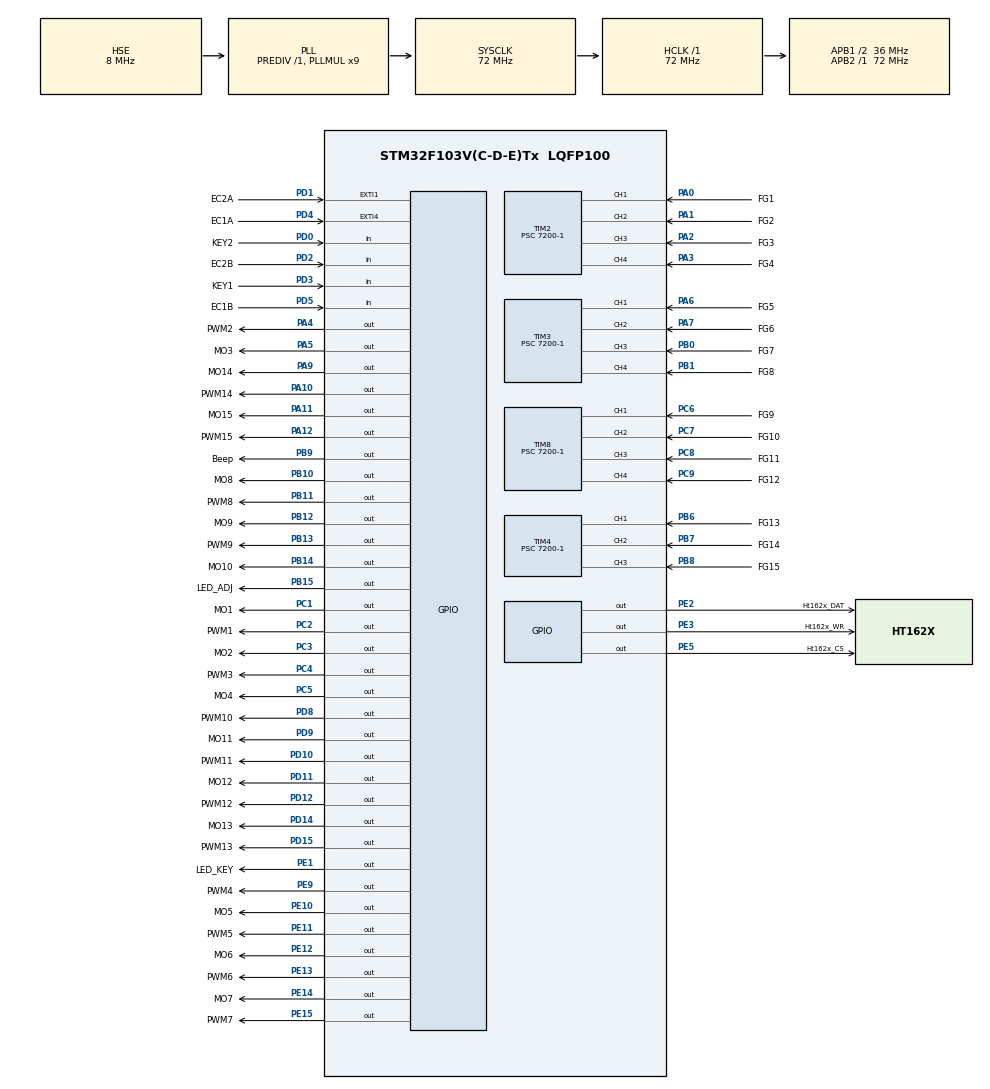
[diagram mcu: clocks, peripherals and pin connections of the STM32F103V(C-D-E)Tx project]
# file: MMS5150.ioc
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Mcu.Family=STM32F1
Mcu.Name=STM32F103V(C-D-E)Tx
Mcu.Package=LQFP100
NVIC.EXTI1_IRQn=true\:0\:0\:false\:false\:true\:true\:true\:true
NVIC.EXTI4_IRQn=true\:0\:0\:false\:false\:true\:true\:true\:true
NVIC.PriorityGroup=NVIC_PRIORITYGROUP_4
NVIC.TIM1_UP_IRQn=true\:3\:0\:true\:false\:true\:true\:true\:true
NVIC.TIM2_IRQn=true\:0\:0\:false\:false\:true\:true\:true\:true
NVIC.TIM3_IRQn=true\:0\:0\:false\:false\:true\:true\:true\:true
NVIC.TIM4_IRQn=true\:0\:0\:false\:false\:true\:true\:true\:true
NVIC.TIM6_IRQn=true\:2\:0\:true\:false\:true\:true\:true\:true
NVIC.TIM8_CC_IRQn=true\:0\:0\:false\:false\:true\:true\:true\:true
OSC_IN.Mode=HSE-External-Oscillator
OSC_IN.Signal=RCC_OSC_IN
OSC_OUT.Mode=HSE-External-Oscillator
OSC_OUT.Signal=RCC_OSC_OUT
PA0-WKUP.GPIO_Label=FG1
PA0-WKUP.Signal=S_TIM2_CH1_ETR
PA1.GPIO_Label=FG2
PA1.Signal=S_TIM2_CH2
PA10.GPIO_Label=PWM14
PA10.Signal=GPIO_Output
PA11.GPIO_Label=MO15
PA11.Signal=GPIO_Output
PA12.GPIO_Label=PWM15
PA12.Signal=GPIO_Output
PA13.Mode=Serial_Wire
PA13.Signal=SYS_JTMS-SWDIO
PA14.Mode=Serial_Wire
PA14.Signal=SYS_JTCK-SWCLK
PA2.GPIO_Label=FG3
PA2.Signal=S_TIM2_CH3
PA3.GPIO_Label=FG4
PA3.Signal=S_TIM2_CH4
PA4.GPIO_Label=PWM2
PA4.Signal=GPIO_Output
PA5.GPIO_Label=MO3
PA5.Signal=GPIO_Output
PA6.GPIO_Label=FG5
PA6.Signal=S_TIM3_CH1
PA7.GPIO_Label=FG6
PA7.Signal=S_TIM3_CH2
PA9.GPIO_Label=MO14
PA9.Signal=GPIO_Output
PB0.GPIO_Label=FG7
PB0.Signal=S_TIM3_CH3
PB1.GPIO_Label=FG8
PB1.Signal=S_TIM3_CH4
PB10.GPIO_Label=MO8
PB10.Signal=GPIO_Output
PB11.GPIO_Label=PWM8
PB11.Signal=GPIO_Output
PB12.GPIO_Label=MO9
PB12.Signal=GPIO_Output
PB13.GPIO_Label=PWM9
PB13.Signal=GPIO_Output
PB14.GPIO_Label=MO10
PB14.Signal=GPIO_Output
PB15.GPIO_Label=LED_ADJ
PB15.Signal=GPIO_Output
PB6.GPIO_Label=FG13
PB6.Signal=S_TIM4_CH1
PB7.GPIO_Label=FG14
PB7.Signal=S_TIM4_CH2
PB8.GPIO_Label=FG15
PB8.Signal=S_TIM4_CH3
PB9.GPIO_Label=Beep
PB9.Signal=GPIO_Output
PC1.GPIO_Label=MO1
PC1.Signal=GPIO_Output
PC2.GPIO_Label=PWM1
PC2.Signal=GPIO_Output
PC3.GPIO_Label=MO2
PC3.Signal=GPIO_Output
PC4.GPIO_Label=PWM3
PC4.Signal=GPIO_Output
PC5.GPIO_Label=MO4
PC5.Signal=GPIO_Output
PC6.GPIO_Label=FG9
PC6.Signal=S_TIM8_CH1
PC7.GPIO_Label=FG10
PC7.Signal=S_TIM8_CH2
PC8.GPIO_Label=FG11
PC8.Signal=S_TIM8_CH3
PC9.GPIO_Label=FG12
PC9.Signal=S_TIM8_CH4
PD0.GPIO_Label=KEY2
PD0.Signal=GPIO_Input
PD1.GPIO_Label=EC2A
PD1.Signal=GPXTI1
PD10.GPIO_Label=PWM11
PD10.Signal=GPIO_Output
PD11.GPIO_Label=MO12
PD11.Signal=GPIO_Output
PD12.GPIO_Label=PWM12
PD12.Signal=GPIO_Output
PD14.GPIO_Label=MO13
PD14.Signal=GPIO_Output
PD15.GPIO_Label=PWM13
PD15.Signal=GPIO_Output
PD2.GPIO_Label=EC2B
PD2.Signal=GPIO_Input
PD3.GPIO_Label=KEY1
PD3.Signal=GPIO_Input
PD4.GPIO_Label=EC1A
PD4.Signal=GPXTI4
PD5.GPIO_Label=EC1B
PD5.Signal=GPIO_Input
PD8.GPIO_Label=PWM10
PD8.Signal=GPIO_Output
PD9.GPIO_Label=MO11
PD9.Signal=GPIO_Output
PE1.GPIO_Label=LED_KEY
PE1.Signal=GPIO_Output
PE10.GPIO_Label=MO5
PE10.Signal=GPIO_Output
PE11.GPIO_Label=PWM5
PE11.Signal=GPIO_Output
PE12.GPIO_Label=MO6
PE12.Signal=GPIO_Output
PE13.GPIO_Label=PWM6
PE13.Signal=GPIO_Output
PE14.GPIO_Label=MO7
PE14.Signal=GPIO_Output
PE15.GPIO_Label=PWM7
PE15.Signal=GPIO_Output
PE2.GPIO_Label=Ht162x_DAT
PE2.GPIO_PuPd=GPIO_PULLUP
PE2.GPIO_Speed=GPIO_SPEED_FREQ_HIGH
PE2.PinState=GPIO_PIN_SET
PE2.Signal=GPIO_Output
PE3.GPIO_Label=Ht162x_WR
PE3.GPIO_ModeDefaultOutputPP=GPIO_MODE_OUTPUT_PP
PE3.GPIO_PuPd=GPIO_PULLUP
PE3.GPIO_Speed=GPIO_SPEED_FREQ_HIGH
PE3.PinState=GPIO_PIN_SET
PE3.Signal=GPIO_Output
PE5.GPIO_Label=Ht162x_CS
PE5.GPIO_PuPd=GPIO_PULLUP
PE5.GPIO_Speed=GPIO_SPEED_FREQ_HIGH
PE5.PinState=GPIO_PIN_SET
PE5.Signal=GPIO_Output
PE9.GPIO_Label=PWM4
PE9.Signal=GPIO_Output
ProjectManager.HeapSize=0x200
ProjectManager.StackSize=0x400
ProjectManager.TargetToolchain=MDK-ARM V5.32
RCC.AHBFreq_Value=72000000
RCC.APB1CLKDivider=RCC_HCLK_DIV2
RCC.APB1Freq_Value=36000000
RCC.APB1TimFreq_Value=72000000
RCC.APB2Freq_Value=72000000
RCC.APB2TimFreq_Value=72000000
RCC.HCLKFreq_Value=72000000
RCC.PLLMUL=RCC_PLL_MUL9
RCC.PLLSourceVirtual=RCC_PLLSOURCE_HSE
RCC.SYSCLKFreq_VALUE=72000000
RCC.SYSCLKSource=RCC_SYSCLKSOURCE_PLLCLK
RCC.USBFreq_Value=72000000
SH.S_TIM2_CH1_ETR.0=TIM2_CH1,Input_Capture1_from_TI1
SH.S_TIM2_CH2.0=TIM2_CH2,Input_Capture2_from_TI2
SH.S_TIM2_CH3.0=TIM2_CH3,Input_Capture3_from_TI3
SH.S_TIM2_CH4.0=TIM2_CH4,Input_Capture4_from_TI4
SH.S_TIM3_CH1.0=TIM3_CH1,Input_Capture1_from_TI1
SH.S_TIM3_CH2.0=TIM3_CH2,Input_Capture2_from_TI2
SH.S_TIM3_CH3.0=TIM3_CH3,Input_Capture3_from_TI3
SH.S_TIM3_CH4.0=TIM3_CH4,Input_Capture4_from_TI4
SH.S_TIM4_CH1.0=TIM4_CH1,Input_Capture1_from_TI1
SH.S_TIM4_CH2.0=TIM4_CH2,Input_Capture2_from_TI2
SH.S_TIM4_CH3.0=TIM4_CH3,Input_Capture3_from_TI3
SH.S_TIM8_CH1.0=TIM8_CH1,Input_Capture1_from_TI1
SH.S_TIM8_CH2.0=TIM8_CH2,Input_Capture2_from_TI2
SH.S_TIM8_CH3.0=TIM8_CH3,Input_Capture3_from_TI3
SH.S_TIM8_CH4.0=TIM8_CH4,Input_Capture4_from_TI4
TIM1.Period=16-1
TIM1.Prescaler=72-1
TIM2.Channel-Input_Capture1_from_TI1=TIM_CHANNEL_1
TIM2.Channel-Input_Capture2_from_TI2=TIM_CHANNEL_2
TIM2.Channel-Input_Capture3_from_TI3=TIM_CHANNEL_3
TIM2.Channel-Input_Capture4_from_TI4=TIM_CHANNEL_4
TIM2.ICFilter_CH1=8
TIM2.ICFilter_CH2=8
TIM2.ICFilter_CH3=8
TIM2.ICFilter_CH4=8
TIM2.Prescaler=7200-1
TIM3.Channel-Input_Capture1_from_TI1=TIM_CHANNEL_1
TIM3.Channel-Input_Capture2_from_TI2=TIM_CHANNEL_2
TIM3.Channel-Input_Capture3_from_TI3=TIM_CHANNEL_3
TIM3.Channel-Input_Capture4_from_TI4=TIM_CHANNEL_4
TIM3.ICFilter_CH1=8
TIM3.ICFilter_CH2=8
TIM3.ICFilter_CH3=8
TIM3.ICFilter_CH4=8
TIM3.Prescaler=7200-1
TIM4.Channel-Input_Capture1_from_TI1=TIM_CHANNEL_1
TIM4.Channel-Input_Capture2_from_TI2=TIM_CHANNEL_2
TIM4.Channel-Input_Capture3_from_TI3=TIM_CHANNEL_3
TIM4.ICFilter_CH1=8
TIM4.ICFilter_CH2=8
TIM4.ICFilter_CH3=8
TIM4.Prescaler=7200-1
TIM6.Period=16-1
TIM6.Prescaler=71
TIM8.Channel-Input_Capture1_from_TI1=TIM_CHANNEL_1
TIM8.Channel-Input_Capture2_from_TI2=TIM_CHANNEL_2
TIM8.Channel-Input_Capture3_from_TI3=TIM_CHANNEL_3
TIM8.Channel-Input_Capture4_from_TI4=TIM_CHANNEL_4
TIM8.ICFilter_CH1=8
TIM8.ICFilter_CH2=8
TIM8.ICFilter_CH3=8
TIM8.ICFilter_CH4=8
TIM8.Prescaler=7200-1
VP_TIM1_VS_ClockSourceINT.Mode=Internal
VP_TIM6_VS_ClockSourceINT.Mode=Enable_Timer
board=custom

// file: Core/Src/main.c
/* USER CODE BEGIN Header */
/**
  ******************************************************************************
  * @file           : main.c
  * @brief          : Main program body
  ******************************************************************************
  * @attention
  *
  * Copyright (c) 2024 STMicroelectronics.
  * All rights reserved.
  *
  * This software is licensed under terms that can be found in the LICENSE file
  * in the root directory of this software component.
  * If no LICENSE file comes with this software, it is provided AS-IS.
  *
  ******************************************************************************
  */
/* USER CODE END Header */
#include "main.h"
#include "tim.h"
#include "gpio.h"

void SystemClock_Config(void);

int main(void)
{

  /* MCU Configuration--------------------------------------------------------*/

  /* Reset of all peripherals, Initializes the Flash interface and the Systick. */
  HAL_Init();

  /* Configure the system clock */
  SystemClock_Config();

  /* Initialize all configured peripherals */
  MX_GPIO_Init();
  MX_TIM1_Init();
  MX_TIM2_Init();
  MX_TIM3_Init();
  MX_TIM4_Init();
  MX_TIM8_Init();
  MX_TIM6_Init();
  /* USER CODE BEGIN 2 */
    System_Init();//ϵͳ������ʼ��
  /* USER CODE END 2 */

  /* Infinite loop */
  /* USER CODE BEGIN WHILE */
  while (1)
  {
      Show_Display();
    /* USER CODE END WHILE */

  }
}

void SystemClock_Config(void)
{
  RCC_OscInitTypeDef RCC_OscInitStruct = {0};
  RCC_ClkInitTypeDef RCC_ClkInitStruct = {0};

  /** Initializes the RCC Oscillators according to the specified parameters
  * in the RCC_OscInitTypeDef structure.
  */
  RCC_OscInitStruct.OscillatorType = RCC_OSCILLATORTYPE_HSE;
  RCC_OscInitStruct.HSEState = RCC_HSE_ON;
  RCC_OscInitStruct.HSEPredivValue = RCC_HSE_PREDIV_DIV1;
  RCC_OscInitStruct.HSIState = RCC_HSI_ON;
  RCC_OscInitStruct.PLL.PLLState = RCC_PLL_ON;
  RCC_OscInitStruct.PLL.PLLSource = RCC_PLLSOURCE_HSE;
  RCC_OscInitStruct.PLL.PLLMUL = RCC_PLL_MUL9;
  if (HAL_RCC_OscConfig(&RCC_OscInitStruct) != HAL_OK)
  {
    Error_Handler();
  }

  /** Initializes the CPU, AHB and APB buses clocks
  */
  RCC_ClkInitStruct.ClockType = RCC_CLOCKTYPE_HCLK|RCC_CLOCKTYPE_SYSCLK
                              |RCC_CLOCKTYPE_PCLK1|RCC_CLOCKTYPE_PCLK2;
  RCC_ClkInitStruct.SYSCLKSource = RCC_SYSCLKSOURCE_PLLCLK;
  RCC_ClkInitStruct.AHBCLKDivider = RCC_SYSCLK_DIV1;
  RCC_ClkInitStruct.APB1CLKDivider = RCC_HCLK_DIV2;
  RCC_ClkInitStruct.APB2CLKDivider = RCC_HCLK_DIV1;

  if (HAL_RCC_ClockConfig(&RCC_ClkInitStruct, FLASH_LATENCY_2) != HAL_OK)
  {
    Error_Handler();
  }
}

void Error_Handler(void)
{
  __disable_irq();
  while (1)
  {
  }
}
